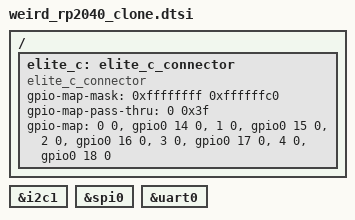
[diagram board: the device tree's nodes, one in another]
/*
 * Copyright (c) 2020 Pete Johanson
 *
 * SPDX-License-Identifier: MIT
 */

/ {
	elite_c: elite_c_connector {
		compatible = "elite_c_connector";
		#gpio-cells = <2>;
		gpio-map-mask = <0xffffffff 0xffffffc0>;
		gpio-map-pass-thru = <0 0x3f>;
		gpio-map
			= <0 0 &gpio0 14 0>		/* D12 */
			, <1 0 &gpio0 15 0>		/* D13 */
			, <2 0 &gpio0 16 0>		/* D14 */
			, <3 0 &gpio0 17 0>		/* D15 */
			, <4 0 &gpio0 18 0>		/* D16 */
			;
	};

};

pro_micro_i2c: &i2c1 {};
pro_micro_spi: &spi0 {};
pro_micro_serial: &uart0 {};
